# N32H7xx register map
Vendor: Nationstech Ltd.; File version: 1.0
CPU: CM7 r1p1, little endian, MPU, FPU, 4 interrupt priority bits
Registers are 32-bit, read-write, reset 0x0 unless marked. A register's access mark holds for its fields unless they carry their own. Offsets are from the block's base; [hi:lo] are bit positions; {n}, {i} and the like mark numbered series.

## SPI1 — Serial peripheral interface
Base 0x400DC000
Same registers: SPI3 0x4000E400, I2S3 0x4000F400, I2S4 0x4000F800, I2S1 0x400DB800, I2S2 0x400DBC00, SPI2 0x400DC400, SPI4 0x58002000, SPI5 0x58002400, SPI6 0x58002800, SPI7 0x58002C00
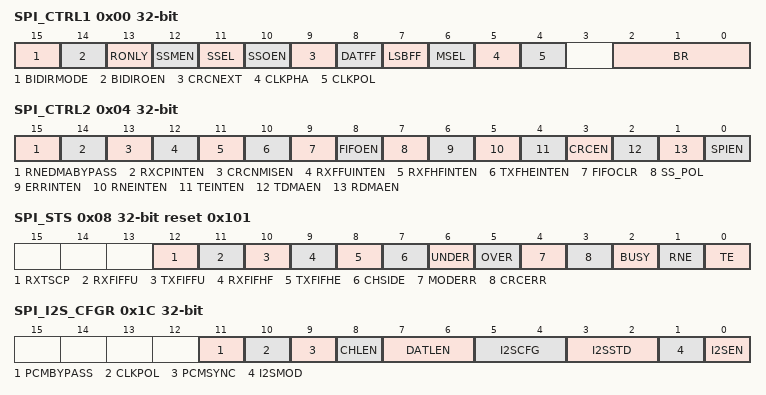
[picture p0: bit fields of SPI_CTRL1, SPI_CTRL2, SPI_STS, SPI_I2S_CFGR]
0x00 SPI_CTRL1
  [15] BIDIRMODE, [14] BIDIROEN, [13] RONLY, [12] SSMEN, [11] SSEL, [10] SSOEN, [9] CRCNEXT, [8] DATFF, [7] LSBFF, [6] MSEL, [5] CLKPHA, [4] CLKPOL, [2:0] BR
0x04 SPI_CTRL2
  [15] RNEDMABYPASS, [14] RXCPINTEN, [13] CRCNMISEN, [12] RXFFUINTEN, [11] RXFHFINTEN, [10] TXFHEINTEN, [9] FIFOCLR, [8] FIFOEN, [7] SS_POL, [6] ERRINTEN, [5] RNEINTEN, [4] TEINTEN, [3] CRCEN, [2] TDMAEN, [1] RDMAEN, [0] SPIEN
0x08 SPI_STS reset 0x101
  [12] RXTSCP, [11] RXFIFFU, [10] TXFIFFU, [9] RXFIFHF, [8] TXFIFHE, [7] CHSIDE, [6] UNDER, [5] OVER, [4] MODERR, [3] CRCERR, [2] BUSY, [1] RNE, [0] TE
0x0C SPI_DAT
  [15:0] DAT
0x10 SPI_CRCTDAT ro
  [15:0] CRCTDAT
0x14 SPI_CRCRDAT ro
  [15:0] CRCRDAT
0x18 SPI_CRCPOLY reset 0x7
  [15:0] CRCPOLY
0x1C SPI_I2S_CFGR
  [11] PCMBYPASS
  [10] CLKPOL
  [9] PCMSYNC
  [8] CHLEN
  [7:6] DATLEN
  [5:4] I2SCFG
  [3:2] I2SSTD
  [1] I2SMOD
  [0] I2SEN — I2SE
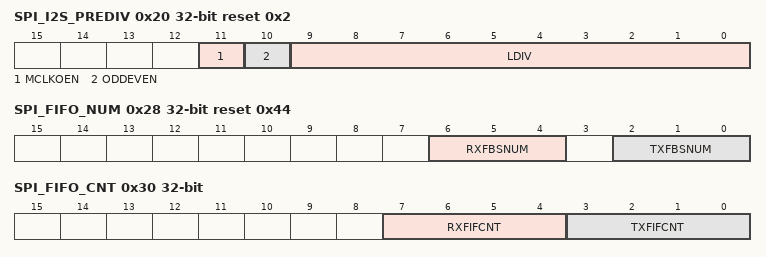
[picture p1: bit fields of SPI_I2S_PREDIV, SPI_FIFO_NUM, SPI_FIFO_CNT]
0x20 SPI_I2S_PREDIV reset 0x2
  [11] MCLKOEN, [10] ODDEVEN, [9:0] LDIV
0x24 SPI_RX_FIFO
  [15:0] RXFIFDAT
0x28 SPI_FIFO_NUM reset 0x44
  [6:4] RXFBSNUM, [2:0] TXFBSNUM
0x30 SPI_FIFO_CNT ro
  [7:4] RXFIFCNT, [3:0] TXFIFCNT
0x34 SPI_TRANS_NUM
  [15:0] TRANSNUM
0x38 SPI_CR3
  [3:0] DELAYTIME

## I2S1_EXT — Inter—IC Sound
Base 0x400DBA00
Same registers: I2S3_EXT 0x4000F600, I2S4_EXT 0x4000FA00, I2S2_EXT 0x400DBE00
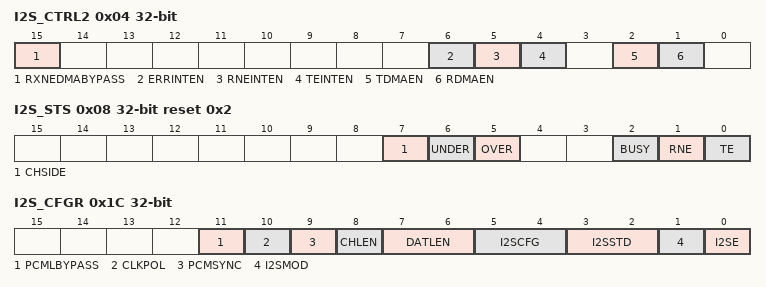
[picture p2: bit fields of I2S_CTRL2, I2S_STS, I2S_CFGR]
0x04 I2S_CTRL2
  [15] RXNEDMABYPASS ro, [6] ERRINTEN, [5] RNEINTEN, [4] TEINTEN, [2] TDMAEN, [1] RDMAEN
0x08 I2S_STS ro reset 0x2
  [7] CHSIDE, [6] UNDER, [5] OVER, [2] BUSY, [1] RNE, [0] TE
0x0C I2S_DAT
  [15:0] DAT
0x1C I2S_CFGR
  [11] PCMLBYPASS, [10] CLKPOL, [9] PCMSYNC, [8] CHLEN, [7:6] DATLEN, [5:4] I2SCFG, [3:2] I2SSTD, [1] I2SMOD, [0] I2SE

## ATIM1 — Advanced timer
Base 0x400DB000
Same registers: ATIM2 0x400DB400, ATIM3 0x58004000, ATIM4 0x58004400
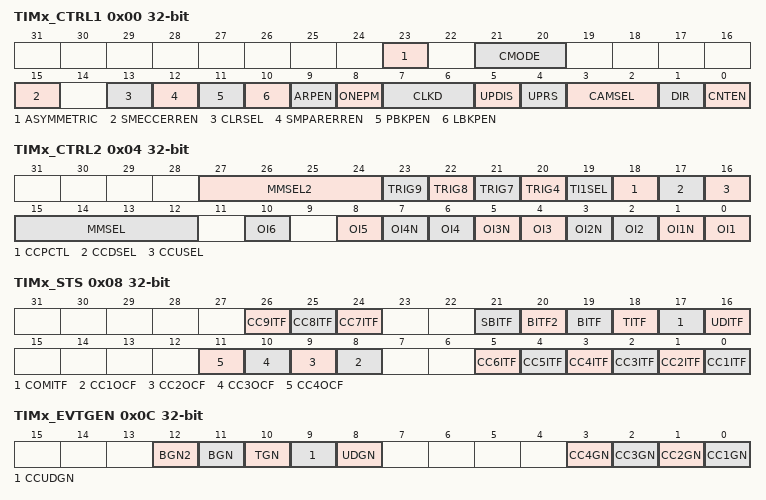
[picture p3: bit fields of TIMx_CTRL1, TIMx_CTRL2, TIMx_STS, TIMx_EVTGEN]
0x00 TIMx_CTRL1
  [23] ASYMMETRIC, [21:20] CMODE, [15] SMECCERREN wo, [13] CLRSEL, [12] SMPARERREN wo, [11] PBKPEN wo, [10] LBKPEN wo, [9] ARPEN, [8] ONEPM, [7:6] CLKD, [5] UPDIS, [4] UPRS, [3:2] CAMSEL, [1] DIR, [0] CNTEN
0x04 TIMx_CTRL2
  [27:24] MMSEL2, [23] TRIG9, [22] TRIG8, [21] TRIG7, [20] TRIG4, [19] TI1SEL, [18] CCPCTL, [17] CCDSEL, [16] CCUSEL, [15:12] MMSEL, [2n-2] OI{n} (n=1..6), [2n-1] OI{n}N (n=1..4)
0x08 TIMx_STS
  [26] CC9ITF, [25] CC8ITF, [24] CC7ITF, [21] SBITF, [20] BITF2, [19] BITF, [18] TITF, [17] COMITF, [16] UDITF, [n+7] CC{n}OCF (n=1..4), [n-1] CC{n}ITF (n=1..6)
0x0C TIMx_EVTGEN wo
  [12] BGN2, [11] BGN, [10] TGN, [9] CCUDGN, [8] UDGN, [n-1] CC{n}GN (n=1..4)
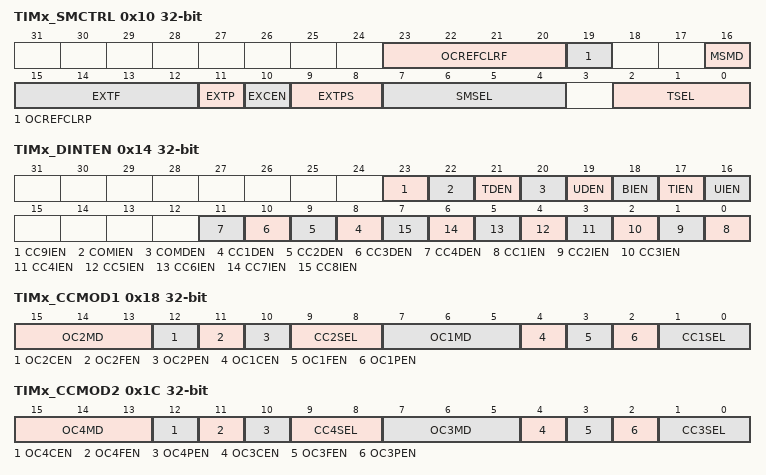
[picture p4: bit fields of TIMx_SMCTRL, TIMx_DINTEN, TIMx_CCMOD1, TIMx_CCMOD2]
0x10 TIMx_SMCTRL
  [23:20] OCREFCLRF, [19] OCREFCLRP, [16] MSMD, [15:12] EXTF, [11] EXTP, [10] EXCEN, [9:8] EXTPS, [7:4] SMSEL, [2:0] TSEL
0x14 TIMx_DINTEN
  [23] CC9IEN, [22] COMIEN, [21] TDEN, [20] COMDEN, [19] UDEN, [18] BIEN, [17] TIEN, [16] UIEN, [n+7] CC{n}DEN (n=1..4), [n-1] CC{n}IEN (n=1..8)
0x18 TIMx_CCMOD1
  [15:13] OC2MD, [12] OC2CEN, [11] OC2FEN, [10] OC2PEN, [9:8] CC2SEL, [7:5] OC1MD, [4] OC1CEN, [3] OC1FEN, [2] OC1PEN, [1:0] CC1SEL
0x1C TIMx_CCMOD2
  [15:13] OC4MD, [12] OC4CEN, [11] OC4FEN, [10] OC4PEN, [9:8] CC4SEL, [7:5] OC3MD, [4] OC3CEN, [3] OC3FEN, [2] OC3PEN, [1:0] CC3SEL
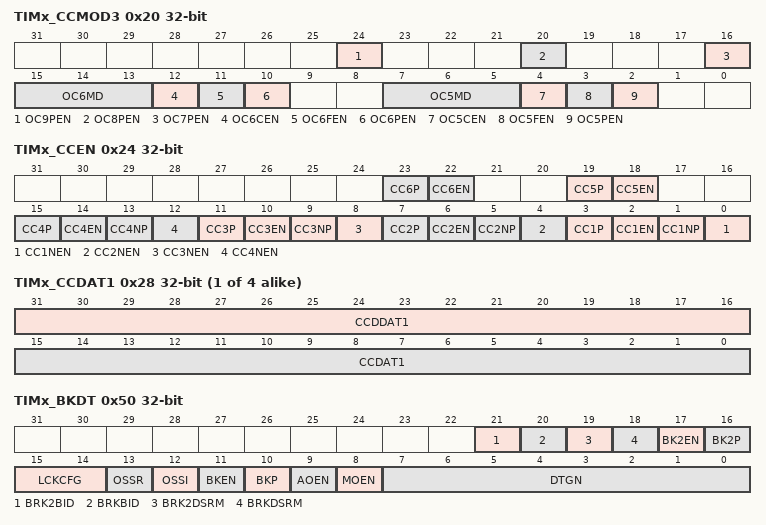
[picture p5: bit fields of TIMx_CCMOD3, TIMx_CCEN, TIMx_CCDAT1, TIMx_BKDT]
0x20 TIMx_CCMOD3
  [24] OC9PEN, [20] OC8PEN, [16] OC7PEN, [15:13] OC6MD, [12] OC6CEN, [11] OC6FEN, [10] OC6PEN, [7:5] OC5MD, [4] OC5CEN, [3] OC5FEN, [2] OC5PEN
0x24 TIMx_CCEN
  [4n-1] CC{n}P (n=1..6), [4n-2] CC{n}EN (n=1..6), [4n-3] CC{n}NP (n=1..4), [4n-4] CC{n}NEN (n=1..4)
{0x24+4i} TIMx_CCDAT{i} (i=1..4)
  [31:16] CCDDAT{i}, [15:0] CCDAT{i}
0x38 TIMx_CCDAT5
  [15:0] CCDAT5
0x3C TIMx_CCDAT6
  [15:0] CCDAT6
0x40 TIMx_PSC
  [15:0] PSC
0x44 TIMx_AR reset 0xFFFF
  [15:0] AR
0x48 TIMx_CNT
  [15:0] CNT
0x4C TIMx_REPCNT
  [7:0] REPCNT
0x50 TIMx_BKDT
  [21] BRK2BID, [20] BRKBID, [19] BRK2DSRM, [18] BRKDSRM, [17] BK2EN, [16] BK2P, [15:14] LCKCFG, [13] OSSR, [12] OSSI, [11] BKEN, [10] BKP, [9] AOEN, [8] MOEN, [7:0] DTGN
{0x38+4i} TIMx_CCDAT{i} (i=7..9)
  [15:0] CCDAT{i}
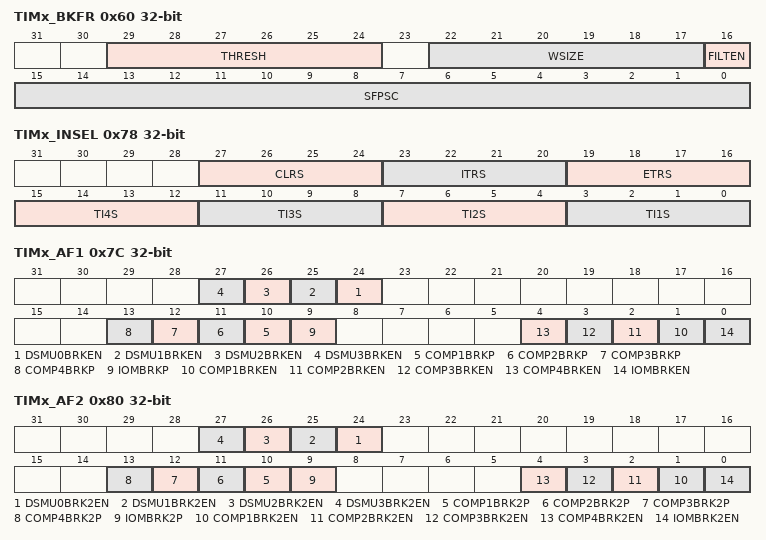
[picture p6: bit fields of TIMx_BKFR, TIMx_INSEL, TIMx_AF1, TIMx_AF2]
0x60 TIMx_BKFR
  [29:24] THRESH, [22:17] WSIZE, [16] FILTEN, [15:0] SFPSC
0x78 TIMx_INSEL
  [27:24] CLRS, [23:20] ITRS, [19:16] ETRS, [4n-1:4n-4] TI{n}S (n=1..4)
0x7C TIMx_AF1
  [n+24] DSMU{n}BRKEN (n=0..3), [n+9] COMP{n}BRKP (n=1..4), [9] IOMBRKP, [n] COMP{n}BRKEN (n=1..4), [0] IOMBRKEN
0x80 TIMx_AF2
  [n+24] DSMU{n}BRK2EN (n=0..3), [n+9] COMP{n}BRK2P (n=1..4), [9] IOMBRK2P, [n] COMP{n}BRK2EN (n=1..4), [0] IOMBRK2EN
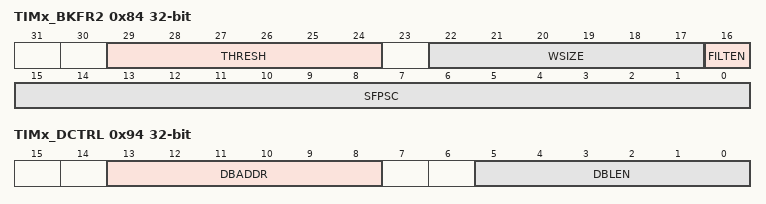
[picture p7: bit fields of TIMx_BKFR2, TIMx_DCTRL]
0x84 TIMx_BKFR2
  [29:24] THRESH, [22:17] WSIZE, [16] FILTEN, [15:0] SFPSC
0x94 TIMx_DCTRL
  [13:8] DBADDR, [5:0] DBLEN
0x98 TIMx_DADDR
  [31:0] BURST
